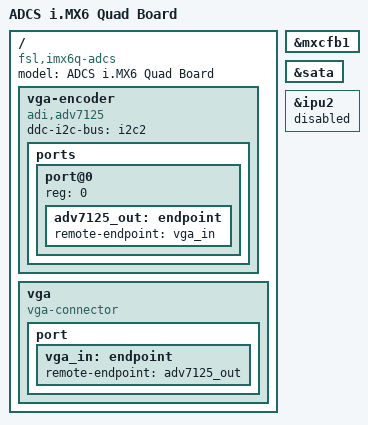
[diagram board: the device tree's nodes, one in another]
/*
 * Copyright 2012=2015 Freescale Semiconductor, Inc.
 * Copyright 2011 Linaro Ltd.
 *
 * The code contained herein is licensed under the GNU General Public
 * License. You may obtain a copy of the GNU General Public License
 * Version 2 or later at the following locations:
 *
 * http://www.opensource.org/licenses/gpl-license.html
 * http://www.gnu.org/copyleft/gpl.html
 */

/dts-v1/;

#include "imx6q.dtsi"
#include "imx6qdl-adcs.dtsi"

/ {
	model = "ADCS i.MX6 Quad Board";
	compatible = "fsl,imx6q-adcs", "fsl,imx6q";
	
	
		vga-encoder {
		compatible = "adi,adv7125";
		ddc-i2c-bus = <&i2c2>;
		ports {
			#address-cells = <1>;
			#size-cells = <0>;

			 
			port@0 {
				reg = <0>;
				adv7125_out: endpoint {
					remote-endpoint = <&vga_in>;
				};
			};
		};
	};

	vga {
		compatible = "vga-connector";

		port {
			vga_in: endpoint {
				remote-endpoint = <&adv7125_out>;
			};
		};
	};
	


};
 

 /*
&ldb {
	status = "okay";
	lvds-channel@0 {
		crtc = "ipu1-di0";
	};

	lvds-channel@1 {
		crtc = "ipu1-di1";
		};
	}; */
&mxcfb1 {
	status = "okay";
};
/*
&mxcfb2 {
	status = "okay";
};

&mxcfb3 {
	status = "okay";
};

&mxcfb4 {
	status = "okay";
};
*/
&sata {
	status = "okay";
};
&ipu2{
	status = "disabled";
};
